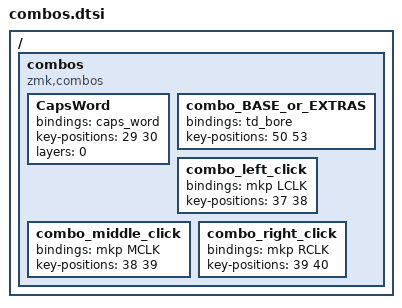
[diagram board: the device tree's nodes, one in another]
/ {
    combos {
        compatible = "zmk,combos";

        CapsWord {
            bindings = <&caps_word>;
            key-positions = <29 30>;
            layers = <0>;
        };

        combo_BASE_or_EXTRAS {
            bindings = <&td_bore>;
            key-positions = <50 53>;
        };
        
        combo_left_click {
            bindings = <&mkp LCLK>;
            key-positions = <37 38>;
        };
        
        combo_middle_click {
            bindings = <&mkp MCLK>;
            key-positions = <38 39>;
        };

        combo_right_click {
            bindings = <&mkp RCLK>;
            key-positions = <39 40>;
        };
    };
};
